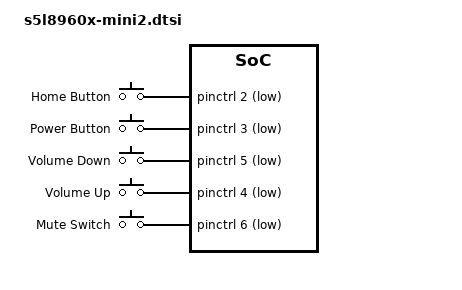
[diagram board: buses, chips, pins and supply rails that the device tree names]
// SPDX-License-Identifier: GPL-2.0+ OR MIT
/*
 * Apple iPad mini 2 common device tree
 * Based on A7 (APL0698), up to 1.3GHz
 *
 * Copyright (c) 2022, Konrad Dybcio <konradybcio@kernel.org>
 */

#include "s5l8960x.dtsi"
#include "s5l8960x-common.dtsi"
#include <dt-bindings/input/input.h>

/ {
	chassis-type = "tablet";

	gpio-keys {
		compatible = "gpio-keys";

		button-home {
			label = "Home Button";
			gpios = <&pinctrl 2 GPIO_ACTIVE_LOW>;
			linux,code = <KEY_HOMEPAGE>;
			wakeup-source;
		};

		button-power {
			label = "Power Button";
			gpios = <&pinctrl 3 GPIO_ACTIVE_LOW>;
			linux,code = <KEY_POWER>;
			wakeup-source;
		};

		button-voldown {
			label = "Volume Down";
			gpios = <&pinctrl 5 GPIO_ACTIVE_LOW>;
			linux,code = <KEY_VOLUMEDOWN>;
		};

		button-volup {
			label = "Volume Up";
			gpios = <&pinctrl 4 GPIO_ACTIVE_LOW>;
			linux,code = <KEY_VOLUMEUP>;
		};

		switch-mute {
			label = "Mute Switch";
			gpios = <&pinctrl 6 GPIO_ACTIVE_LOW>;
			linux,code = <KEY_MUTE>;
		};
	};
};
